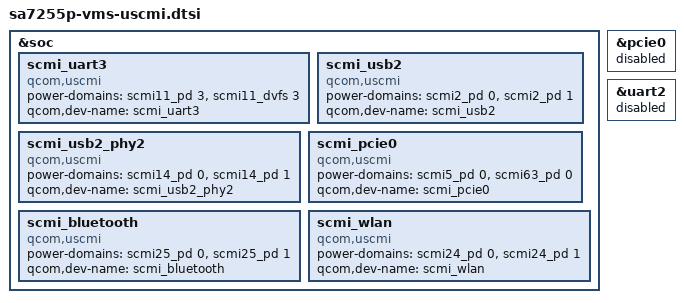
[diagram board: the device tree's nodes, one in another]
// SPDX-License-Identifier: BSD-3-Clause
/*
 * Copyright (c) Qualcomm Technologies, Inc. and/or its subsidiaries.
 */
&soc {
	scmi_uart3 {
		compatible = "qcom,uscmi";
		power-domains = <&scmi11_pd 3>, <&scmi11_dvfs 3>;
		power-domain-names = "power", "perf";
		qcom,dev-name = "scmi_uart3";
	};

	/* SCMI node for USB2 controller power management */
	scmi_usb2 {
		compatible = "qcom,uscmi";
		power-domains = <&scmi2_pd 0>, <&scmi2_pd 1>;
		power-domain-names = "usb_transfer", "usb_core";
		qcom,dev-name = "scmi_usb2";
	};

	scmi_usb2_phy2 {
		compatible = "qcom,uscmi";
		power-domains = <&scmi14_pd 0>, <&scmi14_pd 1>;
		power-domain-names = "usb_transfer", "usb_core";
		qcom,dev-name = "scmi_usb2_phy2";
	};

	scmi_pcie0 {
		compatible = "qcom,uscmi";
		power-domains = <&scmi5_pd 0>, <&scmi63_pd 0>;
		power-domain-names = "power", "dummy";
		qcom,dev-name = "scmi_pcie0";
	};

	scmi_bluetooth {
		compatible = "qcom,uscmi";
		power-domains = <&scmi25_pd 0>, <&scmi25_pd 1>;
		power-domain-names = "power_regulator", "power_gpio";
		qcom,dev-name = "scmi_bluetooth";
	};

	scmi_wlan {
		compatible = "qcom,uscmi";
		power-domains = <&scmi24_pd 0>, <&scmi24_pd 1>;
		power-domain-names = "power_regulator", "power_gpio";
		qcom,dev-name = "scmi_wlan";
	};
};

&pcie0 {
	status = "disabled";
};

&uart2 {
	status = "disabled";
};

